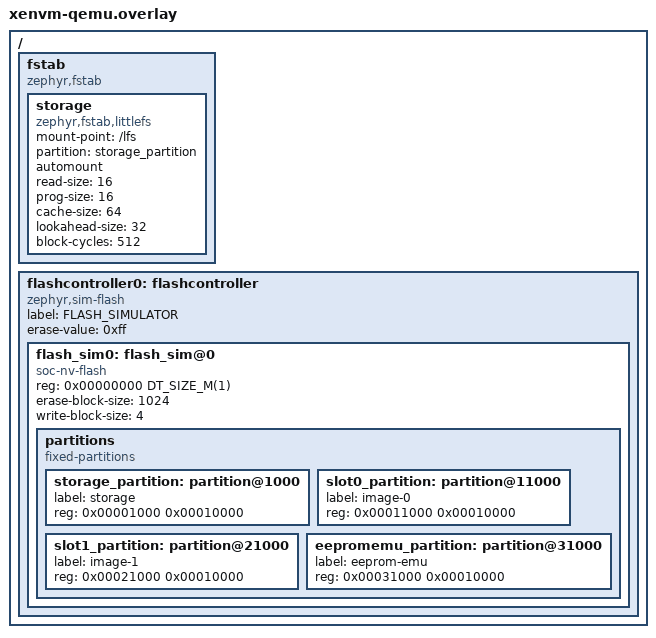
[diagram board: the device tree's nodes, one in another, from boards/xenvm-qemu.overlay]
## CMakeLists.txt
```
# SPDX-License-Identifier: Apache-2.0

cmake_minimum_required(VERSION 3.13.1)

find_package(Zephyr REQUIRED HINTS $ENV{ZEPHYR_BASE})

include($ENV{ZEPHYR_BASE}/cmake/app/boilerplate.cmake NO_POLICY_SCOPE)

set(UTILS_SCRIPTS_DIR ${CMAKE_CURRENT_SOURCE_DIR}/scripts)
if (DTC)
  add_custom_target(
    fix_dtb
    DEPENDS ${ZEPHYR_FINAL_EXECUTABLE}
    COMMAND ${UTILS_SCRIPTS_DIR}/fix_dtb.sh ${UTILS_SCRIPTS_DIR}/gicv2.tmpl ${ZEPHYR_BINARY_DIR}/virt_gicv2.dtb ${ZEPHYR_BINARY_DIR}/zephyr.bin)
else()
  message(WARNING "No dtc program")
endif()

project(xen-dom0)

include_directories(app PRIVATE ${CMAKE_CURRENT_SOURCE_DIR}/include)

# Add prebuilt to includes so assembler can find this files
include_directories(app PRIVATE ${CMAKE_CURRENT_SOURCE_DIR}/prebuilt)

target_sources(app PRIVATE src/dom0.c src/domd_cfg.c src/domain_bins.S)

include(ExternalProject)
set(XEN_SRCDIR ${CMAKE_CURRENT_SOURCE_DIR}/../xen)
set(XEN_BINDIR ${CMAKE_CURRENT_BINARY_DIR}/hyp)

ExternalProject_Add(
  hypervisor
  PREFIX ${XEN_BINDIR}
  SOURCE_DIR ${XEN_SRCDIR}/xen
  BINARY_DIR ${XEN_BINDIR}
  CONFIGURE_COMMAND ""
  BUILD_COMMAND ${MAKE} make -C ${XEN_SRCDIR}/xen O=${XEN_BINDIR}
  CONFIG_QEMU_XEN=y CONFIG_DEBUG=y XSM_ENABLE=y
  XEN_TARGET_ARCH=arm64 CROSS_COMPILE=aarch64-linux-gnu- HOSTCC=gcc
  INSTALL_COMMAND cp ${XEN_BINDIR}/xen ${ZEPHYR_BINARY_DIR}/xen
  )

add_dependencies(app hypervisor)
```

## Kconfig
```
# Copyright (c) 2024 EPAM Systems
#
# SPDX-License-Identifier: Apache-2.0

config USE_DEFAULT_DOM_CFG
	bool "Use default guest domain cfg"
	default y
	help
	  Use default guest domain cfg from domu_cfg.c for build.
	  if not selected the guest domain cfg source file will be selected as basing
	  on board/platform:
	    dom_cfg/${BOARD}.c.
	  For example, for RPI 5 the dom_cfg/rpi_5.c will be used.

config DOM_CFG_BOARD_EXT
	string "Use extention string to determine guest domain cfg"
	depends on !USE_DEFAULT_DOM_CFG
	help
	  Use it to add extention string to determine guest domain cfg file to build.
	  The guest domain cfg source file will be selected as following:
	    dom_cfg/${BOARD}_${DOM_CFG_BOARD_EXT}.c
	  This allows to specify number of guest domain configs for the same board.
	  For example:
	    rpi_5_xenvm.c
	    rpi_5_domu.c

config DOM_STORAGE_FATFS_ENABLE
	bool "Enable FATFS disk storage for reading domains kernels/dtb images"
	default n
	select DISK_ACCESS
	select FILE_SYSTEM
	select FAT_FILESYSTEM_ELM
	select XRUN
	help
	  Enables FATFS disk storage and adds possibility to read guest domains
	  kernels/dtb images from storage.

if DOM_STORAGE_FATFS_ENABLE

config FS_FATFS_MOUNT_MKFS
	default n

config FS_FATFS_WINDOW_ALIGNMENT
	default SDHC_BUFFER_ALIGNMENT

config FS_FATFS_LBA64
	default y

config FS_FATFS_EXFAT
	default y

config DOM_STORAGE_FATFS_DIR
	string "FATFS folder where domains kernels/dtb images"
	default "dom0/"
	help
	  FATFS folder where domains kernels/dtb images are located.
	  It should be ended with "/" symbol.

config DOM_STORAGE_FATFS_LOGICAL_DRIVE_NAME
	string "FATFS logical drive name to be used as mount point"
	default "0" if FS_MULTI_PARTITION
	default SDMMC_VOLUME_NAME
	help
	  FATFS logical drive name to be used as mount point.

config DOM_CFG_LINUX_PV_DOMAIN
	bool "Enable PV domain support loaded from FATFS storage"
	help
	  Adds Linux-based domain with enabled pvnet and pvblock devices.
	  It is expected to be placed on the storage device, connected to
	  Dom0.

endif #DOM_STORAGE_FATFS_ENABLE

config DOM_CFG_BUILTIN_IMAGES
	bool "Use built-in guest domains kernel/device-tree images"
	default y
	help
	  Use built-in guest domains kernel/device-tree images.

if DOM_CFG_BUILTIN_IMAGES

config DOM_CFG_DOMU0_IMAGE_BIN_FILE
	string "Location for Domain-U0 kernel binary"
	default "domu0_img.bin"

config DOM_CFG_DOMU0_DTB_BIN_FILE
	string "Location for Domain-U0 device-tree"
	default "domu0.dtb"

config DOM_CFG_DOMU1_IMAGE_BIN_FILE
	string "Location for Domain-U1 kernel binary"

config DOM_CFG_DOMU1_DTB_BIN_FILE
	string "Location for Domain-U1 device-tree"

endif #DOM_CFG_BUILTIN_IMAGES

source "Kconfig.zephyr"
```

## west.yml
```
# SPDX-License-Identifier: Apache-2.0
# West YAML manifest for Zephyr as Xen Dom0

manifest:
  self:
    path: zephyr-dom0-xt

  remotes:
    - name: xentroops
      url-base: https://github.com/xen-troops/
    - name: zephyrproject-rtos
      url-base: https://github.com/zephyrproject-rtos/

  projects:
    - name: zephyr
      remote: xentroops
      revision: rpi5_dev
      west-commands: scripts/west-commands.yml
    - name: zephyr-xenlib
      remote: xentroops
      revision: main
    - name: fatfs
      remote: zephyrproject-rtos
      revision: 427159bf95ea49b7680facffaa29ad506b42709b
```

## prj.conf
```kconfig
CONFIG_MP_NUM_CPUS=1
CONFIG_XEN_STORE_SRV=y
CONFIG_XEN_DOMAIN_MANAGEMENT=y
CONFIG_XEN_SHELL=y
CONFIG_XEN_LIBFDT=y
CONFIG_XRUN=y
CONFIG_JSON_LIBRARY=y
```

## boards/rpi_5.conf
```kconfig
# Copyright (c) 2024 EPAM Systems
# SPDX-License-Identifier: Apache-2.0

CONFIG_XEN_DOM0=y

CONFIG_XSTAT=y
CONFIG_XSTAT_SHELL_CMDS=y

CONFIG_SHELL_STACK_SIZE=4096

CONFIG_MAIN_STACK_SIZE=8192
CONFIG_ISR_STACK_SIZE=8192

CONFIG_XEN_VCH=y
CONFIG_XEN_DOM0LESS_BOOT=y

CONFIG_USE_DEFAULT_DOM_CFG=n
CONFIG_DOM_CFG_BUILTIN_IMAGES=n

CONFIG_DOM_STORAGE_FATFS_ENABLE=y

CONFIG_FILE_SYSTEM_SHELL=y

CONFIG_NOCACHE_MEMORY=y
CONFIG_FS_MULTI_PARTITION=y
CONFIG_DOM_STORAGE_FATFS_LOGICAL_DRIVE_NAME="1"
CONFIG_DOM_STORAGE_FATFS_DIR="dom0/"
CONFIG_XEN_LIBFDT=y

CONFIG_DOM_CFG_LINUX_PV_DOMAIN=y
```

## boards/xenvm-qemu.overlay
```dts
#include <mem.h>

/ {
  	fstab {
		compatible = "zephyr,fstab";
		storage: storage {
			compatible = "zephyr,fstab,littlefs";
			mount-point = "/lfs";
			partition = <&storage_partition>;
			automount;
			read-size = <16>;
			prog-size = <16>;
			cache-size = <64>;
			lookahead-size = <32>;
			block-cycles = <512>;
		};
	};
	flashcontroller0: flashcontroller {
		compatible = "zephyr,sim-flash";
		label = "FLASH_SIMULATOR";
		#address-cells = <1>;
		#size-cells = <1>;
		erase-value = <0xff>;
		flash_sim0: flash_sim@0 {
			compatible = "soc-nv-flash";
			reg = <0x00000000 DT_SIZE_M(1)>;
			erase-block-size = <1024>;
			write-block-size = <4>;
			partitions {
				compatible = "fixed-partitions";
				#address-cells = <1>;
				#size-cells = <1>;
			/*
			 * Storage partition will be used by FCB/LittleFS/NVS
			 * if enabled.
			 */
				storage_partition: partition@1000 {
					label = "storage";
					reg = <0x00001000 0x00010000>;
				};
				slot0_partition: partition@11000 {
					 label = "image-0";
					 reg = <0x00011000 0x00010000>;
				};
				slot1_partition: partition@21000 {
					 label = "image-1";
					 reg = <0x00021000 0x00010000>;
				};
				eepromemu_partition: partition@31000 {
					label = "eeprom-emu";
					reg = <0x00031000 0x00010000>;
				};
			};
		};
	};
};
```

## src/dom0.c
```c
/*
 * Copyright (c) 2024 EPAM Systems
 *
 * SPDX-License-Identifier: Apache-2.0
 */

#include <domain.h>
#include <zephyr/kernel.h>
#include <zephyr/logging/log.h>

LOG_MODULE_REGISTER(dom0);

#include "dom0.h"

extern struct dom0_domain_cfg domain_cfgs[];

int domain_get_user_cfg_count(void)
{
	int i = 0;

	while (domain_cfgs[i].domain_cfg) {
		i++;
	}

	return i;
}

struct xen_domain_cfg *domain_get_user_cfg(int index)
{
	if (index < domain_get_user_cfg_count()) {
		return domain_cfgs[index].domain_cfg;
	}

	return NULL;
}

int main(void)
{
	int ret;
	int i = 0;

	ret = storage_init();
	if (ret) {
		goto exit_err;
	}

	/* init domains cfg */
	while (domain_cfgs[i].domain_cfg) {
		domain_cfgs[i].domain_cfg->image_info = &domain_cfgs[i];
		i++;
	}

exit_err:
	return ret;
}
```

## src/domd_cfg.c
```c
/*
 * Copyright (c) 2023 EPAM Systems
 *
 * SPDX-License-Identifier: Apache-2.0
 */

#include <domain.h>
#include <string.h>
#include <zephyr/xen/public/domctl.h>

static char *domd_dtdevs[] = {
	    "/soc/dma-controller@e6460000",
	    "/soc/dma-controller@e6470000",
	    "/soc/dma-controller@e6700000",
	    "/soc/dma-controller@e7300000",
	    "/soc/dma-controller@e7310000",
	    "/soc/dma-controller@ec700000",
	    "/soc/dma-controller@ec720000",
	    "/soc/ethernet@e6800000",
	    "/soc/video@e6ef0000",
	    "/soc/video@e6ef1000",
	    "/soc/video@e6ef2000",
	    "/soc/video@e6ef3000",
	    "/soc/video@e6ef4000",
	    "/soc/video@e6ef5000",
	    "/soc/video@e6ef6000",
	    "/soc/video@e6ef7000",
	    "/soc/usb@ee000000",
	    "/soc/dma-controller@e65a0000",
	    "/soc/dma-controller@e65b0000",
	    "/soc/mmc@ee100000",
	    "/soc/mmc@ee140000",
	    "/soc/mmc@ee160000",
	    "/soc/usb@ee080100",
	    "/soc/usb@ee020000",
	    "/soc/usb@ee0a0100",
	    "/soc/usb@ee0c0100",
	    "/soc/usb@ee080000",
	    "/soc/usb@ee0a0000",
	    "/soc/usb@ee0c0000",
	    "/soc/imr-lx4@fe860000",
	    "/soc/imr-lx4@fe870000",
	    "/soc/imr-lx4@fe880000",
	    "/soc/imr-lx4@fe890000",
	    "/soc/vspm@fe920000",
	    "/soc/vspm@fe960000",
	    "/soc/vspm@fe9a0000",
	    "/soc/vspm@fe9b0000",
	    "/soc/fcp@fea27000",
	    "/soc/fcp@fea2f000",
	    "/soc/fcp@fea37000",
	    "/soc/fdpm@fe940000",
	    "/soc/fdpm@fe944000",
	    "/soc/hdmi@fead0000",
	    "/soc/hdmi@feae0000",
	    "/soc/gsx_pv0_domd",
	    "/soc/gsx_pv1_domd",
	    "/soc/gsx_pv2_domd",
	    "/soc/gsx_pv3_domd",
	    "/soc/fcpcs_vc0",
	    "/soc/fcpcs_vc1",
	    "/soc/pcie@fe000000",
	    "/soc/pcie@ee800000",
	    "/soc/impdm0",
	    "/soc/dma-controller@ffc10000",
	    "/soc/dma-controller@ffc20000",
};

static struct xen_domain_iomem domd_iomems[] = {

	/* #re-mapped MM_LOSSY_SHARED_MEM_ADDR page */
	{ .first_gfn = 0xe0000, .first_mfn = 0x47fd7, .nr_mfns = 0x1 },
	{ .first_mfn = 0xe6260, .nr_mfns = 0x1},
	{ .first_mfn = 0xe6020, .nr_mfns = 0x1},
	{ .first_mfn = 0xe6050, .nr_mfns = 0x1},
	{ .first_mfn = 0xe6051, .nr_mfns = 0x1},
	{ .first_mfn = 0xe6052, .nr_mfns = 0x1},	/* GPIO2 */
	{ .first_mfn = 0xe6053, .nr_mfns = 0x1},
	{ .first_mfn = 0xe6054, .nr_mfns = 0x1},
	{ .first_mfn = 0xe6055, .nr_mfns = 0x1},
	{ .first_mfn = 0xe6060, .nr_mfns = 0x1},	/* PFC */
	{ .first_mfn = 0xe60a0, .nr_mfns = 0x1},
	{ .first_mfn = 0xe6150, .nr_mfns = 0x1},	/* CPG */
	{ .first_mfn = 0xe6160, .nr_mfns = 0x1},	/* RST */
	{ .first_mfn = 0xe6180, .nr_mfns = 0x1},	/* SYSC */
	{ .first_mfn = 0xe6198, .nr_mfns = 0x1},
	{ .first_mfn = 0xe61a0, .nr_mfns = 0x1},
	{ .first_mfn = 0xe61a8, .nr_mfns = 0x1},
	{ .first_mfn = 0xe61c0, .nr_mfns = 0x1},
	{ .first_mfn = 0xe6510, .nr_mfns = 0x1},
	{ .first_mfn = 0xe66d8, .nr_mfns = 0x1},
	{ .first_mfn = 0xe60b0, .nr_mfns = 0x1},
	{ .first_mfn = 0xe6550, .nr_mfns = 0x1},
	{ .first_mfn = 0xe6590, .nr_mfns = 0x1},
	{ .first_mfn = 0xe65a0, .nr_mfns = 0x1},
	{ .first_mfn = 0xe65b0, .nr_mfns = 0x1},
	{ .first_mfn = 0xe6460, .nr_mfns = 0x1},
	{ .first_mfn = 0xe6470, .nr_mfns = 0x1},
	{ .first_mfn = 0xe65ee, .nr_mfns = 0x1},
	{ .first_mfn = 0xe6601, .nr_mfns = 0x1},
	{ .first_mfn = 0xe6700, .nr_mfns = 0x10},
	{ .first_mfn = 0xe7300, .nr_mfns = 0x10},
	{ .first_mfn = 0xe7310, .nr_mfns = 0x10},
	{ .first_mfn = 0xe67e0, .nr_mfns = 0x11},
	{ .first_mfn = 0xe6800, .nr_mfns = 0x1},	/* EtherAVB */
	{ .first_mfn = 0xe6a00, .nr_mfns = 0x10},	/* EtherAVB */
	{ .first_mfn = 0xe6e31, .nr_mfns = 0x1},
	{ .first_mfn = 0xe6e32, .nr_mfns = 0x1},
	{ .first_mfn = 0xe6ef0, .nr_mfns = 0x1},
	{ .first_mfn = 0xe6ef1, .nr_mfns = 0x1},
	{ .first_mfn = 0xe6ef2, .nr_mfns = 0x1},
	{ .first_mfn = 0xe6ef3, .nr_mfns = 0x1},
	{ .first_mfn = 0xe6ef4, .nr_mfns = 0x1},
	{ .first_mfn = 0xe6ef5, .nr_mfns = 0x1},
	{ .first_mfn = 0xe6ef6, .nr_mfns = 0x1},
	{ .first_mfn = 0xe6ef7, .nr_mfns = 0x1},
	{ .first_mfn = 0xec500, .nr_mfns = 0x1},
	{ .first_mfn = 0xec5a0, .nr_mfns = 0x1},
	{ .first_mfn = 0xec540, .nr_mfns = 0x1},
	{ .first_mfn = 0xec541, .nr_mfns = 0x1},
	{ .first_mfn = 0xec760, .nr_mfns = 0x1},
	{ .first_mfn = 0xec000, .nr_mfns = 0x1},
	{ .first_mfn = 0xec008, .nr_mfns = 0x1},
	{ .first_mfn = 0xec700, .nr_mfns = 0x10},
	{ .first_mfn = 0xec720, .nr_mfns = 0x10},
	{ .first_mfn = 0xee000, .nr_mfns = 0x1},
	{ .first_mfn = 0xee020, .nr_mfns = 0x1},
	{ .first_mfn = 0xee080, .nr_mfns = 0x1},
	{ .first_mfn = 0xee0a0, .nr_mfns = 0x1},
	{ .first_mfn = 0xee0c0, .nr_mfns = 0x1},
	{ .first_mfn = 0xee100, .nr_mfns = 0x2},
	{ .first_mfn = 0xee140, .nr_mfns = 0x2},
	{ .first_mfn = 0xee160, .nr_mfns = 0x2},
	{ .first_mfn = 0xfd000, .nr_mfns = 0x40},
	{ .first_mfn = 0xfe000, .nr_mfns = 0x80},
	{ .first_mfn = 0xee800, .nr_mfns = 0x80},
	{ .first_mfn = 0xfe860, .nr_mfns = 0x2},
	{ .first_mfn = 0xfe870, .nr_mfns = 0x2},
	{ .first_mfn = 0xfe880, .nr_mfns = 0x2},
	{ .first_mfn = 0xfe890, .nr_mfns = 0x2},
	{ .first_mfn = 0xfe90f, .nr_mfns = 0x1},
	{ .first_mfn = 0xfe8d0, .nr_mfns = 0x1},
	{ .first_mfn = 0xfe910, .nr_mfns = 0x1},
	{ .first_mfn = 0xfe900, .nr_mfns = 0x1},
	{ .first_mfn = 0xfe940, .nr_mfns = 0x3},
	{ .first_mfn = 0xfe950, .nr_mfns = 0x1},
	{ .first_mfn = 0xfe944, .nr_mfns = 0x3},
	{ .first_mfn = 0xfe951, .nr_mfns = 0x1},
	{ .first_mfn = 0xfea27, .nr_mfns = 0x1},
	{ .first_mfn = 0xfea2f, .nr_mfns = 0x1},
	{ .first_mfn = 0xfea37, .nr_mfns = 0x1},
	{ .first_mfn = 0xfe960, .nr_mfns = 0x8},
	{ .first_mfn = 0xfe96f, .nr_mfns = 0x1},
	{ .first_mfn = 0xfe920, .nr_mfns = 0x8},
	{ .first_mfn = 0xfe92f, .nr_mfns = 0x1},
	{ .first_mfn = 0xfea20, .nr_mfns = 0x5},
	{ .first_mfn = 0xfea28, .nr_mfns = 0x5},
	{ .first_mfn = 0xfea30, .nr_mfns = 0x5},
	{ .first_mfn = 0xfe9a0, .nr_mfns = 0x8},
	{ .first_mfn = 0xfe9af, .nr_mfns = 0x1},
	{ .first_mfn = 0xfe9b0, .nr_mfns = 0x8},
	{ .first_mfn = 0xfe9bf, .nr_mfns = 0x1},
	{ .first_mfn = 0xfea80, .nr_mfns = 0x10},
	{ .first_mfn = 0xfeaa0, .nr_mfns = 0x10},
	{ .first_mfn = 0xfead0, .nr_mfns = 0x10},
	{ .first_mfn = 0xfeae0, .nr_mfns = 0x10},
	{ .first_mfn = 0xfeb00, .nr_mfns = 0x80},
	{ .first_mfn = 0xfeb90, .nr_mfns = 0x1},
	{ .first_mfn = 0xfff00, .nr_mfns = 0x1},
	{ .first_mfn = 0xffa00, .nr_mfns = 0x4},
	{ .first_mfn = 0xff900, .nr_mfns = 0x20},
	{ .first_mfn = 0xff920, .nr_mfns = 0x20},
	{ .first_mfn = 0xff940, .nr_mfns = 0x20},
	{ .first_mfn = 0xff960, .nr_mfns = 0x20},
	{ .first_mfn = 0xff980, .nr_mfns = 0x10},
	{ .first_mfn = 0xff990, .nr_mfns = 0x10},
	{ .first_mfn = 0xff9c0, .nr_mfns = 0x10},
	{ .first_mfn = 0xffa10, .nr_mfns = 0x4},
	{ .first_mfn = 0xffa40, .nr_mfns = 0x20},
	{ .first_mfn = 0xff8d0, .nr_mfns = 0x1},
	{ .first_mfn = 0x54000, .nr_mfns = 0x3000},
	{ .first_mfn = 0xffc10, .nr_mfns = 0x10},
	{ .first_mfn = 0xffc20, .nr_mfns = 0x10},
	{ .first_mfn = 0xfea40, .nr_mfns = 0x1},
	{ .first_mfn = 0xfea50, .nr_mfns = 0x1},
	{ .first_mfn = 0xfea60, .nr_mfns = 0x1},
	{ .first_mfn = 0xfea70, .nr_mfns = 0x1},
	{ .first_mfn = 0xe6e68, .nr_mfns = 0x1},	/* SCIF1 */
};

static uint32_t domd_irqs[] = {
		// gpio@e6050000
		    36,
		// gpio@e6051000
		    37,
		// gpio@e6052000
		    38,
		// gpio@e6053000
		    39,
		// gpio@e6054000
		    40,
		// gpio@e6055000
		    41,
		// gpio@e6055400
		    42,
		// gpio@e6055800
		    43,
		// thermal@e6198000
		    99, 100, 101,
		// interrupt-controller@e61c0000
		    32, 33, 34, 35, 193, 50,
		// i2c@e6510000
		    318,
		// i2c@e66d8000
		    51,
		// i2c@e60b0000
		    205,
		// serial@e6550000
		    187,
		// usb@e6590000
		    139,
		// dma-controller@e65a0000
		    141,
		// dma-controller@e65b0000
		    142,
		// dma-controller@e6460000
		    66,
		// dma-controller@e6470000
		    67,
		// crypto@e6601000
		    103,
		// dma-controller@e6700000
		    231, 232, 233, 234, 235, 236, 237, 238, 239, 240, 241, 242, 243, 244, 245, 246, 247,
		// dma-controller@e7300000
		    251, 345, 252, 346, 248, 340, 341, 342, 343, 344, 249, 250, 347, 348, 349, 350, 351,
		// dma-controller@e7310000
		    448, 449, 450, 451, 452, 453, 454, 455, 456, 457, 458, 459, 460, 461, 462, 463, 429,
		// ethernet@e6800000
		    71, 72, 73, 74, 75, 76, 77, 78, 79, 80, 81, 82, 83, 84, 85, 86, 87, 88, 89, 90, 91, 92, 93, 94, 95,
		// video@e6ef0000
		    220,
		// video@e6ef1000
		    221,
		// video@e6ef2000
		    222,
		// video@e6ef3000
		    223,
		// video@e6ef4000
		    206,
		// video@e6ef5000
		    207,
		// video@e6ef6000
		    208,
		// video@e6ef7000
		    203,
		// src-0
		    384,
		// src-1
		    385,
		// src-2
		    386,
		// src-3
		    387,
		// src-4
		    388,
		// src-5
		    389,
		// src-6
		    390,
		// src-7
		    391,
		// src-8
		    392,
		// src-9
		    393,
		// ssi-0
		    402,
		// ssi-1
		    403,
		// ssi-2
		    404,
		// ssi-3
		    405,
		// ssi-4
		    406,
		// ssi-5
		    407,
		// ssi-6
		    408,
		// ssi-7
		    409,
		// ssi-8
		    410,
		// ssi-9
		    411,
		// dma-controller@ec700000
		    352, 353, 354, 355, 356, 357, 358, 359, 360, 361, 362, 363, 364, 365, 366, 367, 382,
		// dma-controller@ec720000
		    383, 368, 369, 370, 371, 372, 373, 374, 375, 376, 377, 378, 379, 380, 381, 414, 415,
		// adsp@ec800000
		//   269,
		// usb@ee000000
		    134,
		// usb@ee020000
		    136,
		// usb@ee080000
		    140,
		// usb@ee0a0000
		    144,
		// usb@ee0c0000
		    145,
		// mmc@ee100000
		    197,
		// mmc@ee140000
		    199,
		// mmc@ee160000
		    200,
		// gsx@fd000000
		    151,
		// pcie@fe000000
		    148, 149, 150,
		// pcie@ee800000
		    180, 181, 182,
		// imr-lx4@fe860000
		    224,
		// imr-lx4@fe870000
		    225,
		// imr-lx4@fe880000
		    226,
		// imr-lx4@fe890000
		    227,
		// vcp4@fe8d0000
		    412, 413, 255,
		// vcp4@fe910000
		    292, 293,
		// vcp4@fe900000
		    272, 273,
		// fdpm@fe940000
		    294,
		// fdpm@fe944000
		    295,
		// vspm@fe960000
		    298,
		// vspm@fe920000
		    497,
		// vsp@fea20000
		    498,
		// vsp@fea28000
		    499,
		// vsp@fea30000
		    500,
		// vspm@fe9a0000
		    476,
		// vspm@fe9b0000
		    477,
		// csi2@fea80000
		    216,
		// csi2@feaa0000
		    278,
		// hdmi@fead0000
		    421,
		// hdmi@feae0000
		    468,
		// display@feb00000
		    288, 300, 301, 302,
		// impdes0
		    471,
		// imprtt
		    425,
		// dma-controller@ffc10000
		    480, 481, 482, 483, 484, 485, 486, 487, 488,
		// dma-controller@ffc20000
		    501, 489, 490, 491, 492, 493, 494, 495, 496,
		/* serial@e6e68000 */
			185,
};

extern char __img_domd_start[];
extern char __img_domd_end[];
extern char __dtb_domd_start[];
extern char __dtb_domd_end[];

static int load_image_bytes(uint8_t *buf, size_t bufsize,
			    uint64_t image_load_offset, void *image_info)
{
	memcpy(buf, __img_domd_start + image_load_offset, bufsize);
	return 0;
}

static ssize_t get_image_size(void *image_info, uint64_t *size)
{
	*size = __img_domd_end - __img_domd_start;
	return 0;
}

struct xen_domain_cfg domd_cfg = {
	.mem_kb = 16384,

	.flags = (XEN_DOMCTL_CDF_hvm | XEN_DOMCTL_CDF_hap),
	.max_evtchns = 10,
	.max_vcpus = 4,
	.gnt_frames = 32,
	.max_maptrack_frames = 1,

	.iomems = domd_iomems,
	.nr_iomems = 0,

	.irqs = domd_irqs,
	.nr_irqs = 0,

	.gic_version = XEN_DOMCTL_CONFIG_GIC_V2,
	.tee_type = XEN_DOMCTL_CONFIG_TEE_NONE,

	.dtdevs = domd_dtdevs,
	.nr_dtdevs = 0,

	.load_image_bytes = load_image_bytes,
	.get_image_size = get_image_size,
	.image_info = NULL,

	.dtb_start = __dtb_domd_start,
	.dtb_end = __dtb_domd_end,
};
```
